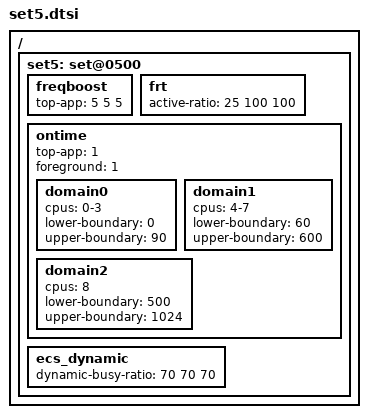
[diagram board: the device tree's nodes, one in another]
/ {
	/* camera mode - default */
	set5: set@0500 {
		/* Boosting margin applied to frequency selection */
		freqboost {			/* LIT MED BIG */
			top-app			= <  5   5   5>;
		};

		frt {	   	     		/* LIT MED BIG */
			active-ratio		= < 25 100 100>;
		};

		/* Ontime Migration */
		ontime {
			top-app		= <1>;
			foreground	= <1>;

			domain0 {
				cpus = "0-3";
				lower-boundary = <0>;
				upper-boundary = <90>;
			};
			domain1 {
				cpus = "4-7";
				lower-boundary = <60>;
				upper-boundary = <600>;
			};
			domain2 {
				cpus = "8";
				lower-boundary = <500>;
				upper-boundary = <1024>;
			};
		};

		ecs_dynamic {
			dynamic-busy-ratio		= <70 70 70>;
		};
	};
};
